# Z32F1281 register map
Vendor: Zilog, Inc; File version: 1.0
CPU: CM3 r1p0, little endian, no MPU, no FPU, 3 interrupt priority bits
Registers are 32-bit, read-write, reset 0x0 unless marked. A register's access mark holds for its fields unless they carry their own. Offsets are from the block's base; [hi:lo] are bit positions; {n}, {i} and the like mark numbered series.

## IC0 — I2C Interface
Base 0x4000A000
Same registers: IC1 0x4000A100
0x00 DR — I2C Data Register
  [7:0] DR — Data
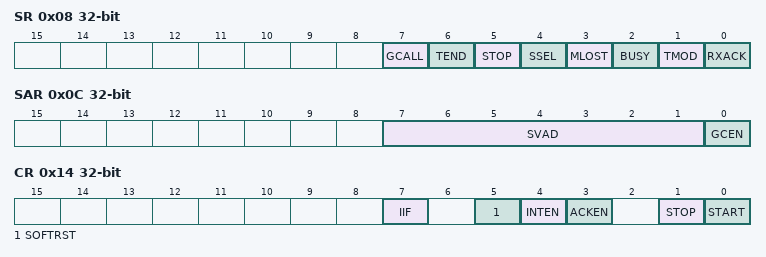
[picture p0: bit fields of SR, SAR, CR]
0x08 SR — Status register
  [7] GCALL — General call flag
  [6] TEND — 1 byte transmission complete flag
  [5] STOP — Stop Flag
  [4] SSEL — slave flag
  [3] MLOST — Mastership lost flag
  [2] BUSY — busy flag
  [1] TMOD — Transmit/reciever mode flag
  [0] RXACK — RX ack flag
0x0C SAR — I2C Slave Address Register
  [7:1] SVAD — 7 bits slave address
  [0] GCEN — general call enable bit
0x14 CR — I2C Control Register
  [7] IIF — Interrupt flag bit
  [5] SOFTRST — Soft reset enable bit
  [4] INTEN — Interrupt enable bit
  [3] ACKEN — ACK enabit bit in receiver mode
  [1] STOP — Stop enable bit
  [0] START — transmission start bit in master mode
0x18 SCLL reset 0xFFFF — I2C SCL LOW duration Register
  [15:0] SCLL — SCL Low duration value
0x1C SCLH reset 0xFFFF — I2C SCL HIGH duration Register
  [15:0] SCLH — SCL High duration value
0x20 SDH (reset mask 0x7F) — SDA Hold Register
  [14:0] SDH — SDA Hold time

## AD0 — 12-BIT A/D CONVERTER
Base 0x4000B000
Same registers: AD1 0x4000B100, AD2 0x4000B200
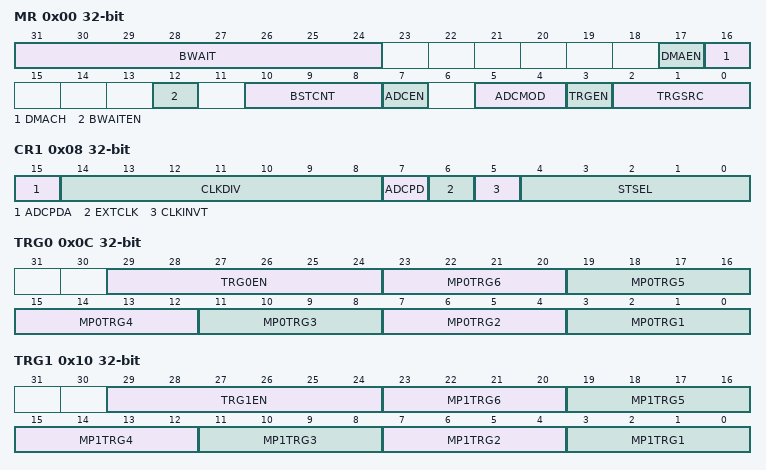
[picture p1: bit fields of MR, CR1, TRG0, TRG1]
0x00 MR — ADCn Mode Register
  [31:24] BWAIT — burst wait count value
  [17] DMAEN — DMA enable
  [16] DMACH — DMA channel option
  [12] BWAITEN — Burst wait enable
  [10:8] BSTCNT — No Burst Mode
  [7] ADCEN — ADC Enable
  [5:4] ADCMOD — ADC convert mode
  [3] TRGEN — Trigger sources enable
  [2:0] TRGSRC — ADC Trigger source sel
0x04 CSR — ADCn Channel Select Register
  [3:0] CHSEL — channel select
0x08 CR1 — ADCn Control Register 1
  [15] ADCPDA — ADC R-ADC disable to save power
  [14:8] CLKDIV — ADC clock divider
  [7] ADCPD — ADC Power down
  [6] EXTCLK — ADCuse external clock
  [5] CLKINVT — divided clock inversion
  [4:0] STSEL — Sampling time selection
0x0C TRG0 — ADC Trigger 0 Channel Register
  [29:24] TRG0EN — MP0TRGn enable
  [4n-1:4n-4] MP0TRG{n} (n=1..6) — ADC channel n select for MPWM0 ADC trigger{n} operation
0x10 TRG1 — ADC Trigger 1 Channel Register
  [29:24] TRG1EN — MP1TRGn enable
  [4n-1:4n-4] MP1TRG{n} (n=1..6) — ADC channel n select for MPWM1 ADC trigger{n} operation
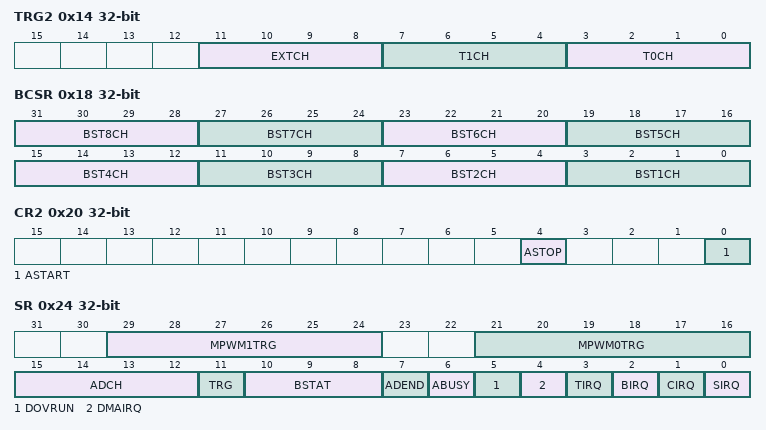
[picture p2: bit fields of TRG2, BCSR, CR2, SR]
0x14 TRG2 — ADC Trigger 2 Channel Register
  [11:8] EXTCH — ADC channel n select for external trigger operation
  [7:4] T1CH — ADC channel n select for timer1 trigger operation
  [3:0] T0CH — ADC channel n select for timer0 trigger operation
0x18 BCSR — ADC Burst Mode Channel select
  [4n-1:4n-4] BST{n}CH (n=4..8) — {n}th burst mode coversion channel selection
  [11:8] BST3CH — 3rd burst mode coversion channel selection
  [7:4] BST2CH — 2nd burst mode coversion channel selection
  [3:0] BST1CH — 1st burst mode coversion channel selection
0x20 CR2 — ADCn Control Register 2
  [4] ASTOP wo — ADC Stop
  [0] ASTART — ADC conversion start
0x24 SR — ADCn Status Register
  [29:24] MPWM1TRG
  [21:16] MPWM0TRG
  [15:12] ADCH — ADC channel bits of present operation
  [11] TRG — Trigger event status
  [10:8] BSTAT — Burst mode operation count status
  [7] ADEND — ADC End Flag
  [6] ABUSY — ADC conversion busy flag
  [5] DOVRUN — DMA overrun flag
  [4] DMAIRQ — DMA received/transfer is done
  [3] TIRQ — ADC Trigger interrupt flag
  [2] BIRQ — ADC burst interrupt flag
  [1] CIRQ — ADC continuous interrupt flag
  [0] SIRQ — ADC single interrupt flag
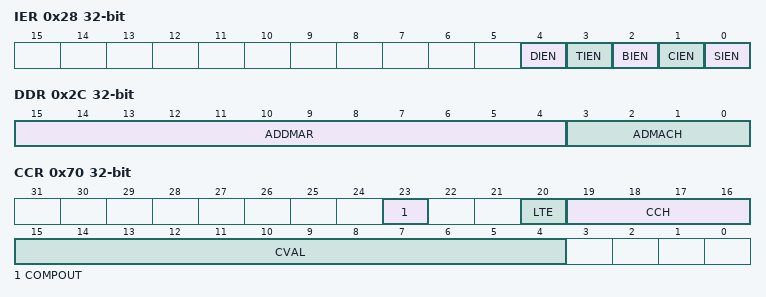
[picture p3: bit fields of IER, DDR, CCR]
0x28 IER — Interrupt Enable Register
  [4] DIEN — DMA done interrupt enable
  [3] TIEN — ADC Trigger conversion intterupt enable
  [2] BIEN — ADC burst conversion interrupt enable
  [1] CIEN — ADC continus conversion interrupt enable
  [0] SIEN — ADC single conversion intterupt enable
0x2C DDR — ADC 0/1/2 DMA Data Register
  [15:4] ADDMAR — ADC conversion result data
  [3:0] ADMACH — ADC data channel indicator
0x70 CCR — ADC Channel Compare Control Register
  [23] COMPOUT ro — ADC compare operation enable
  [20] LTE — compare direction(greater/less)
  [19:16] CCH — compare channel select
  [15:4] CVAL — compare value

## AFE — ANALOG FRONT END
Base 0x4000B300
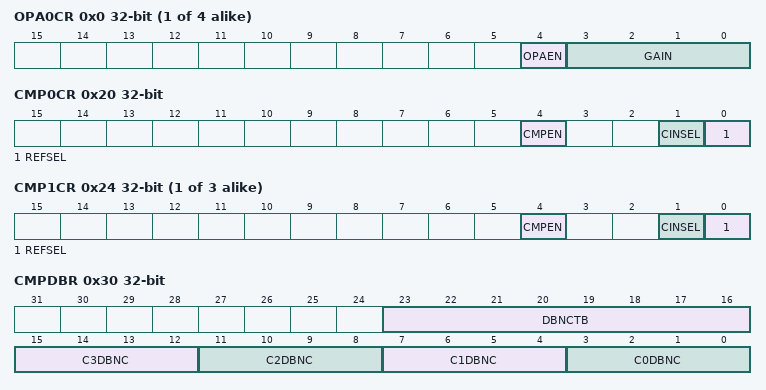
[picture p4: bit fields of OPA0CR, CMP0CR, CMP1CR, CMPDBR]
{0x0+4i} OPA{i}CR (i=0..3) — OPAMP {i} Control Registers
  [4] OPAEN — OPAMP enable
  [3:0] GAIN — OPAMP Gain select
0x20 CMP0CR — Comparator 0 Control Register
  [4] CMPEN — Comparator enable(0)/disable(1)
  [1] CINSEL — Comparator input select
  [0] REFSEL — Comparator reference selection
{0x20+4i} CMP{i}CR (i=1..3) — Comparator {i} Control Register
  [4] CMPEN — Comparator enable
  [1] CINSEL — Comparator input select
  [0] REFSEL — Comparator reference selection
0x30 CMPDBR — Comparator de-bounce Register
  [23:16] DBNCTB — Debounce time base counter
  [4n+3:4n] C{n}DBNC (n=0..3) — Debouce shift selection
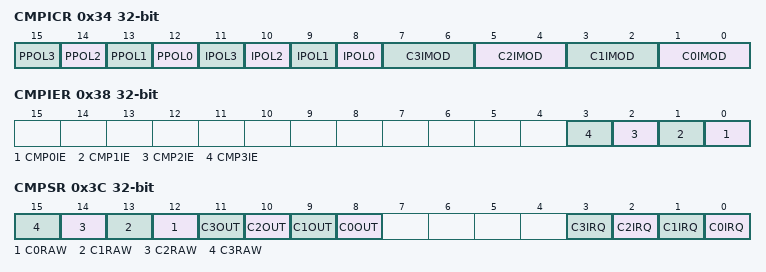
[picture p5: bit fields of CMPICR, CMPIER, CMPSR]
0x34 CMPICR — Comparator Interrupt Control Register
  [n+12] PPOL{n} (n=0..3) — Comparator outs for PWM invert selection
  [n+8] IPOL{n} (n=0..3) — Comparator outs low/high IRQ selection
  [2n+1:2n] C{n}IMOD (n=0..3) — Comparator interrupt mode selection
0x38 CMPIER — Comparator Interrupt Enable Register
  [n] CMP{n}IE (n=0..3) — Comparator Interrupt enable
0x3C CMPSR — Comparator Status Register
  [n+12] C{n}RAW ro (n=0..3) — Comparator raw output before debounce
  [n+8] C{n}OUT ro (n=0..3) — Comparator raw output after debounce
  [n] C{n}IRQ (n=0..3) — Comparator interrupt flag
